VERSION "can_gui protocol 2"

NS_ :

BS_:

BU_: GUI MCU

BO_ 2559879867 GUI_COMMAND: 8 GUI
 SG_ CommandCode M : 0|8@1+ (1,0) [0|255] "" MCU
 SG_ Slot1Enable m1 : 8|1@1+ (1,0) [0|1] "" MCU
 SG_ Slot1ExtendedId m1 : 9|1@1+ (1,0) [0|1] "" MCU
 SG_ Slot1FlagsReserved m1 : 10|6@1+ (1,0) [0|0] "" MCU
 SG_ Slot1CanId m1 : 16|32@1+ (1,0) [0|536870911] "" MCU
 SG_ Slot1CycleTime m1 : 48|16@1+ (1,0) [1|65535] "ms" MCU
 SG_ Slot2Enable m2 : 8|1@1+ (1,0) [0|1] "" MCU
 SG_ Slot2ExtendedId m2 : 9|1@1+ (1,0) [0|1] "" MCU
 SG_ Slot2FlagsReserved m2 : 10|6@1+ (1,0) [0|0] "" MCU
 SG_ Slot2CanId m2 : 16|32@1+ (1,0) [0|536870911] "" MCU
 SG_ Slot2CycleTime m2 : 48|16@1+ (1,0) [1|65535] "ms" MCU
 SG_ LedChannel m16 : 8|8@1+ (1,0) [1|2] "" MCU
 SG_ LedState m16 : 16|8@1+ (1,0) [0|1] "" MCU
 SG_ LedReserved m16 : 24|40@1+ (1,0) [0|0] "" MCU
 SG_ Slot1CounterReserved1 m17 : 8|8@1+ (1,0) [0|0] "" MCU
 SG_ Slot1CounterLimit m17 : 16|32@1+ (1,0) [0|4294967295] "" MCU
 SG_ Slot1CounterReserved2 m17 : 48|16@1+ (1,0) [0|0] "" MCU
 SG_ Slot2CounterReserved1 m18 : 8|8@1+ (1,0) [0|0] "" MCU
 SG_ Slot2CounterLimit m18 : 16|32@1+ (1,0) [0|4294967295] "" MCU
 SG_ Slot2CounterReserved2 m18 : 48|16@1+ (1,0) [0|0] "" MCU
 SG_ RtcTimeHour m32 : 8|8@1+ (1,0) [0|23] "h" MCU
 SG_ RtcTimeMinute m32 : 16|8@1+ (1,0) [0|59] "min" MCU
 SG_ RtcTimeSecond m32 : 24|8@1+ (1,0) [0|59] "s" MCU
 SG_ RtcTimeReserved m32 : 32|32@1+ (1,0) [0|0] "" MCU
 SG_ RtcDateTimeHundredth m33 : 8|8@1+ (1,0) [0|99] "10 ms" MCU
 SG_ RtcDateTimeSecond m33 : 16|8@1+ (1,0) [0|59] "s" MCU
 SG_ RtcDateTimeMinute m33 : 24|8@1+ (1,0) [0|59] "min" MCU
 SG_ RtcDateTimeHour m33 : 32|8@1+ (1,0) [0|23] "h" MCU
 SG_ RtcDateTimeDay m33 : 40|8@1+ (1,0) [1|31] "" MCU
 SG_ RtcDateTimeMonth m33 : 48|5@1+ (1,0) [1|12] "" MCU
 SG_ RtcDateTimeWeekday m33 : 53|3@1+ (1,0) [0|6] "" MCU
 SG_ RtcDateTimeYear m33 : 56|8@1+ (1,0) [0|99] "" MCU
 SG_ AlarmSecondEnabled m34 : 8|1@1+ (1,0) [0|1] "" MCU
 SG_ AlarmMinuteEnabled m34 : 9|1@1+ (1,0) [0|1] "" MCU
 SG_ AlarmHourEnabled m34 : 10|1@1+ (1,0) [0|1] "" MCU
 SG_ AlarmDayEnabled m34 : 11|1@1+ (1,0) [0|1] "" MCU
 SG_ AlarmWeekdayEnabled m34 : 12|1@1+ (1,0) [0|1] "" MCU
 SG_ AlarmFlagsReserved m34 : 13|3@1+ (1,0) [0|0] "" MCU
 SG_ AlarmSecond m34 : 16|8@1+ (1,0) [0|59] "s" MCU
 SG_ AlarmMinute m34 : 24|8@1+ (1,0) [0|59] "min" MCU
 SG_ AlarmHour m34 : 32|8@1+ (1,0) [0|23] "h" MCU
 SG_ AlarmDay m34 : 40|8@1+ (1,0) [0|31] "" MCU
 SG_ AlarmWeekday m34 : 48|8@1+ (1,0) [0|6] "" MCU
 SG_ AlarmReserved m34 : 56|8@1+ (1,0) [0|0] "" MCU
 SG_ LogGetInfoReserved m48 : 8|56@1+ (1,0) [0|0] "" MCU
 SG_ LogReadSequence m49 : 8|32@1+ (1,0) [1|4294967295] "" MCU
 SG_ LogReadReserved m49 : 40|24@1+ (1,0) [0|0] "" MCU
 SG_ PwmFrequency m64 : 8|32@1+ (1,0) [0|1000000] "Hz" MCU
 SG_ PwmDutyCycle m64 : 40|8@1+ (1,0) [0|100] "%" MCU
 SG_ PwmReserved m64 : 48|16@1+ (1,0) [0|0] "" MCU
 SG_ PwmSelfTestStart m65 : 8|8@1+ (1,0) [0|1] "" MCU
 SG_ PwmSelfTestReserved m65 : 16|48@1+ (1,0) [0|0] "" MCU
 SG_ Tic12400BatterySwitchBitmap m80 : 8|24@1+ (1,0) [0|1023] "" MCU
 SG_ Tic12400PolarityReserved m80 : 32|32@1+ (1,0) [0|0] "" MCU

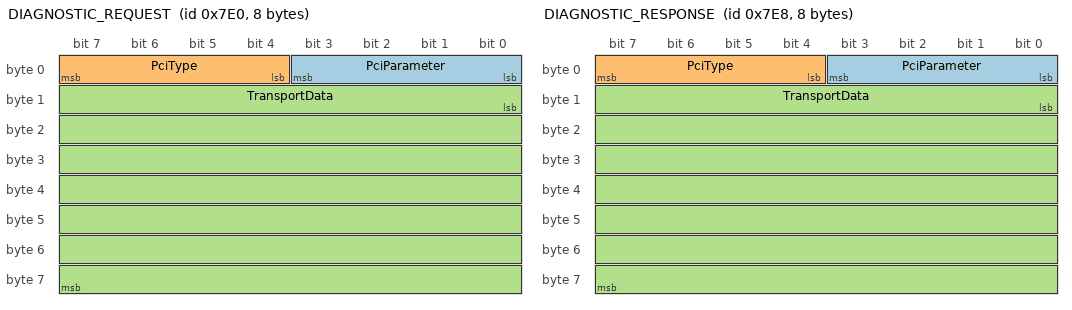
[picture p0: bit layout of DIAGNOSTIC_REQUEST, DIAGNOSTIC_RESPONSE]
BO_ 2016 DIAGNOSTIC_REQUEST: 8 GUI
 SG_ PciParameter : 0|4@1+ (1,0) [0|15] "" MCU
 SG_ PciType : 4|4@1+ (1,0) [0|3] "" MCU
 SG_ TransportData : 8|56@1+ (1,0) [0|72057594037927935] "" MCU

BO_ 2024 DIAGNOSTIC_RESPONSE: 8 MCU
 SG_ PciParameter : 0|4@1+ (1,0) [0|15] "" GUI
 SG_ PciType : 4|4@1+ (1,0) [0|3] "" GUI
 SG_ TransportData : 8|56@1+ (1,0) [0|72057594037927935] "" GUI

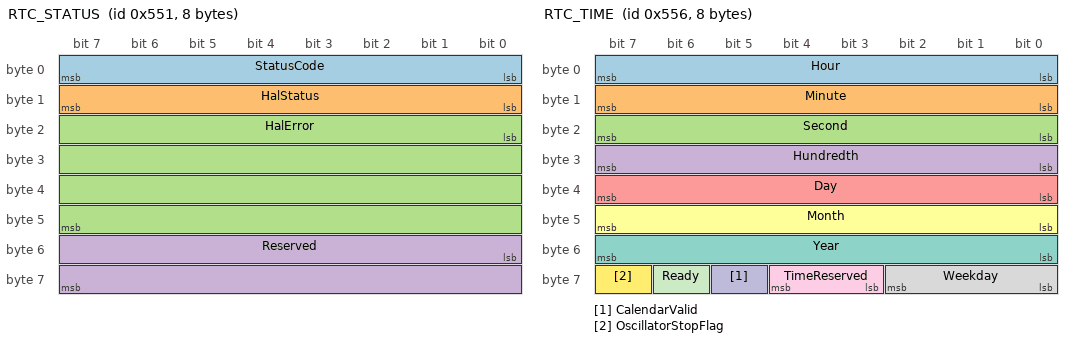
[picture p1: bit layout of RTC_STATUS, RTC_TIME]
BO_ 1361 RTC_STATUS: 8 MCU
 SG_ StatusCode : 0|8@1+ (1,0) [0|255] "" GUI
 SG_ HalStatus : 8|8@1+ (1,0) [0|255] "" GUI
 SG_ HalError : 16|32@1+ (1,0) [0|4294967295] "" GUI
 SG_ Reserved : 48|16@1+ (1,0) [0|0] "" GUI

BO_ 1366 RTC_TIME: 8 MCU
 SG_ Hour : 0|8@1+ (1,0) [0|23] "h" GUI
 SG_ Minute : 8|8@1+ (1,0) [0|59] "min" GUI
 SG_ Second : 16|8@1+ (1,0) [0|59] "s" GUI
 SG_ Hundredth : 24|8@1+ (1,0) [0|99] "10 ms" GUI
 SG_ Day : 32|8@1+ (1,0) [1|31] "" GUI
 SG_ Month : 40|8@1+ (1,0) [1|12] "" GUI
 SG_ Year : 48|8@1+ (1,0) [0|99] "" GUI
 SG_ Weekday : 56|3@1+ (1,0) [0|6] "" GUI
 SG_ TimeReserved : 59|2@1+ (1,0) [0|0] "" GUI
 SG_ CalendarValid : 61|1@1+ (1,0) [0|1] "" GUI
 SG_ Ready : 62|1@1+ (1,0) [0|1] "" GUI
 SG_ OscillatorStopFlag : 63|1@1+ (1,0) [0|1] "" GUI

BO_ 1367 SYSTEM_STATUS: 8 MCU
 SG_ Slot1Running : 0|1@1+ (1,0) [0|1] "" GUI
 SG_ Slot2Running : 1|1@1+ (1,0) [0|1] "" GUI
 SG_ Led1On : 2|1@1+ (1,0) [0|1] "" GUI
 SG_ Led2On : 3|1@1+ (1,0) [0|1] "" GUI
 SG_ SummaryReserved : 4|4@1+ (1,0) [0|0] "" GUI
 SG_ Slot1State : 8|8@1+ (1,0) [0|1] "" GUI
 SG_ Slot2State : 16|8@1+ (1,0) [0|1] "" GUI
 SG_ Led1State : 24|8@1+ (1,0) [0|1] "" GUI
 SG_ Led2State : 32|8@1+ (1,0) [0|1] "" GUI
 SG_ Slot1Requested : 40|1@1+ (1,0) [0|1] "" GUI
 SG_ Slot2Requested : 41|1@1+ (1,0) [0|1] "" GUI
 SG_ Led1Requested : 42|1@1+ (1,0) [0|1] "" GUI
 SG_ Led2Requested : 43|1@1+ (1,0) [0|1] "" GUI
 SG_ PwmRequested : 44|1@1+ (1,0) [0|1] "" GUI
 SG_ RequestReserved : 45|3@1+ (1,0) [0|0] "" GUI
 SG_ SwitchDataValid : 48|1@1+ (1,0) [0|1] "" GUI
 SG_ In0Closed : 49|1@1+ (1,0) [0|1] "" GUI
 SG_ In1Closed : 50|1@1+ (1,0) [0|1] "" GUI
 SG_ In2Closed : 51|1@1+ (1,0) [0|1] "" GUI
 SG_ In3Closed : 52|1@1+ (1,0) [0|1] "" GUI
 SG_ PhysicalReserved : 53|3@1+ (1,0) [0|0] "" GUI
 SG_ Slot1Blocked : 56|1@1+ (1,0) [0|1] "" GUI
 SG_ Slot2Blocked : 57|1@1+ (1,0) [0|1] "" GUI
 SG_ Led1Overridden : 58|1@1+ (1,0) [0|1] "" GUI
 SG_ OverrideReserved3 : 59|1@1+ (1,0) [0|0] "" GUI
 SG_ PwmBlocked : 60|1@1+ (1,0) [0|1] "" GUI
 SG_ OverrideReserved5 : 61|3@1+ (1,0) [0|0] "" GUI

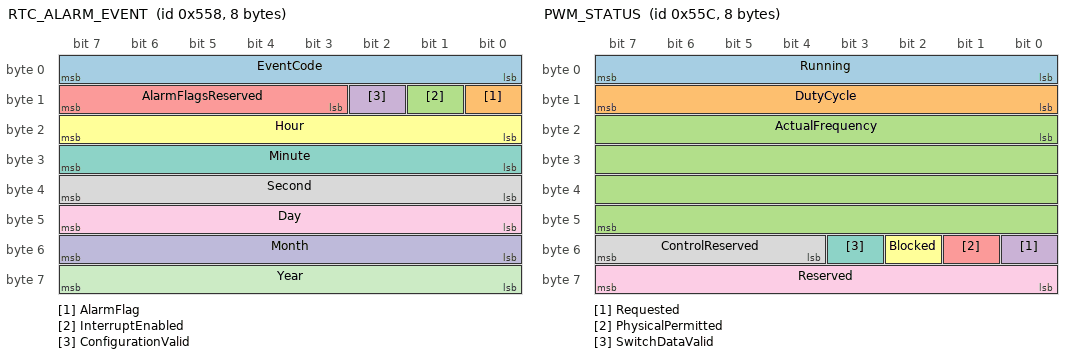
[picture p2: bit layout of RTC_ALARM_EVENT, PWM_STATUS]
BO_ 1368 RTC_ALARM_EVENT: 8 MCU
 SG_ EventCode : 0|8@1+ (1,0) [0|255] "" GUI
 SG_ AlarmFlag : 8|1@1+ (1,0) [0|1] "" GUI
 SG_ InterruptEnabled : 9|1@1+ (1,0) [0|1] "" GUI
 SG_ ConfigurationValid : 10|1@1+ (1,0) [0|1] "" GUI
 SG_ AlarmFlagsReserved : 11|5@1+ (1,0) [0|0] "" GUI
 SG_ Hour : 16|8@1+ (1,0) [0|23] "h" GUI
 SG_ Minute : 24|8@1+ (1,0) [0|59] "min" GUI
 SG_ Second : 32|8@1+ (1,0) [0|59] "s" GUI
 SG_ Day : 40|8@1+ (1,0) [1|31] "" GUI
 SG_ Month : 48|8@1+ (1,0) [1|12] "" GUI
 SG_ Year : 56|8@1+ (1,0) [0|99] "" GUI

BO_ 1372 PWM_STATUS: 8 MCU
 SG_ Running : 0|8@1+ (1,0) [0|1] "" GUI
 SG_ DutyCycle : 8|8@1+ (1,0) [0|100] "%" GUI
 SG_ ActualFrequency : 16|32@1+ (1,0) [0|4294967295] "Hz" GUI
 SG_ Requested : 48|1@1+ (1,0) [0|1] "" GUI
 SG_ PhysicalPermitted : 49|1@1+ (1,0) [0|1] "" GUI
 SG_ Blocked : 50|1@1+ (1,0) [0|1] "" GUI
 SG_ SwitchDataValid : 51|1@1+ (1,0) [0|1] "" GUI
 SG_ ControlReserved : 52|4@1+ (1,0) [0|0] "" GUI
 SG_ Reserved : 56|8@1+ (1,0) [0|0] "" GUI

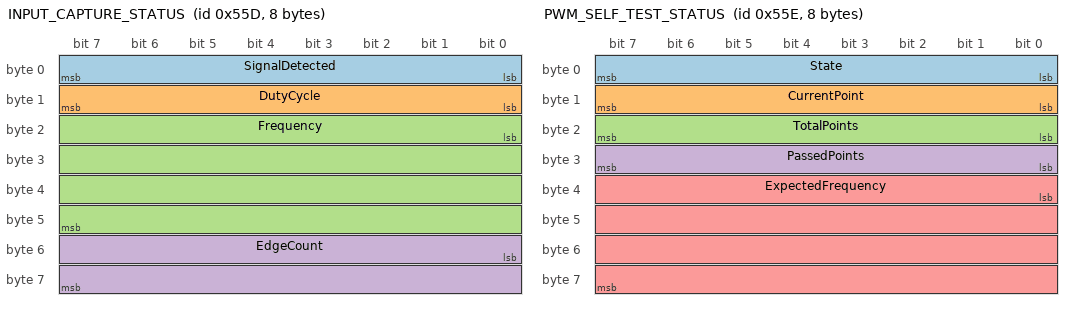
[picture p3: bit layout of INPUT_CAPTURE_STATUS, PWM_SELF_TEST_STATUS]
BO_ 1373 INPUT_CAPTURE_STATUS: 8 MCU
 SG_ SignalDetected : 0|8@1+ (1,0) [0|1] "" GUI
 SG_ DutyCycle : 8|8@1+ (1,0) [0|100] "%" GUI
 SG_ Frequency : 16|32@1+ (1,0) [0|4294967295] "Hz" GUI
 SG_ EdgeCount : 48|16@1+ (1,0) [0|65535] "" GUI

BO_ 1374 PWM_SELF_TEST_STATUS: 8 MCU
 SG_ State : 0|8@1+ (1,0) [0|5] "" GUI
 SG_ CurrentPoint : 8|8@1+ (1,0) [0|255] "" GUI
 SG_ TotalPoints : 16|8@1+ (1,0) [0|255] "" GUI
 SG_ PassedPoints : 24|8@1+ (1,0) [0|255] "" GUI
 SG_ ExpectedFrequency : 32|32@1+ (1,0) [0|4294967295] "Hz" GUI

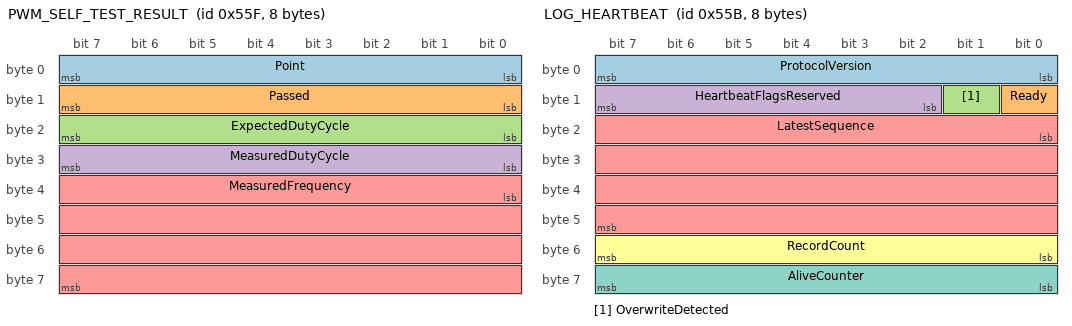
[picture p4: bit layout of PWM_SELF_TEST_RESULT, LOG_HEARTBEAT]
BO_ 1375 PWM_SELF_TEST_RESULT: 8 MCU
 SG_ Point : 0|8@1+ (1,0) [0|255] "" GUI
 SG_ Passed : 8|8@1+ (1,0) [0|1] "" GUI
 SG_ ExpectedDutyCycle : 16|8@1+ (1,0) [0|100] "%" GUI
 SG_ MeasuredDutyCycle : 24|8@1+ (1,0) [0|100] "%" GUI
 SG_ MeasuredFrequency : 32|32@1+ (1,0) [0|4294967295] "Hz" GUI

BO_ 1370 LOG_RESPONSE: 8 MCU
 SG_ FragmentHeader : 0|8@1+ (1,0) [0|255] "" GUI
 SG_ FragmentData : 8|56@1+ (1,0) [0|72057594037927935] "" GUI

BO_ 1371 LOG_HEARTBEAT: 8 MCU
 SG_ ProtocolVersion : 0|8@1+ (1,0) [0|255] "" GUI
 SG_ Ready : 8|1@1+ (1,0) [0|1] "" GUI
 SG_ OverwriteDetected : 9|1@1+ (1,0) [0|1] "" GUI
 SG_ HeartbeatFlagsReserved : 10|6@1+ (1,0) [0|0] "" GUI
 SG_ LatestSequence : 16|32@1+ (1,0) [0|4294967295] "" GUI
 SG_ RecordCount : 48|8@1+ (1,0) [0|64] "" GUI
 SG_ AliveCounter : 56|8@1+ (1,0) [0|255] "" GUI

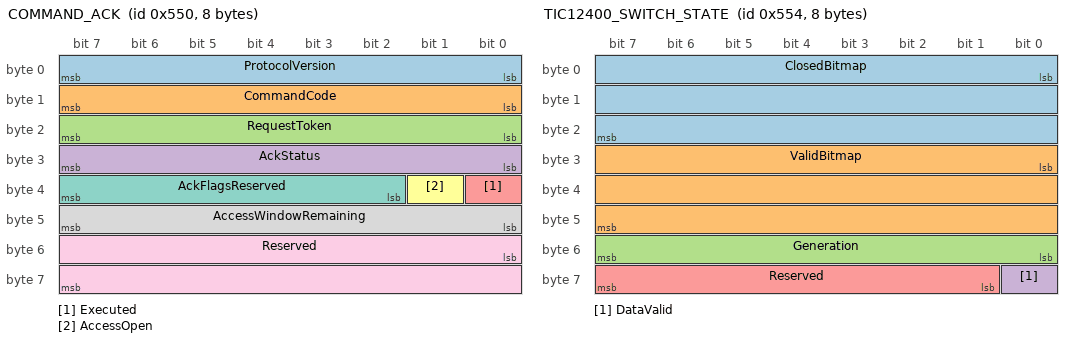
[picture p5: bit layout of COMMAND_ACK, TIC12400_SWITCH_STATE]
BO_ 1360 COMMAND_ACK: 8 MCU
 SG_ ProtocolVersion : 0|8@1+ (1,0) [0|255] "" GUI
 SG_ CommandCode : 8|8@1+ (1,0) [0|255] "" GUI
 SG_ RequestToken : 16|8@1+ (1,0) [0|255] "" GUI
 SG_ AckStatus : 24|8@1+ (1,0) [0|255] "" GUI
 SG_ Executed : 32|1@1+ (1,0) [0|1] "" GUI
 SG_ AccessOpen : 33|1@1+ (1,0) [0|1] "" GUI
 SG_ AckFlagsReserved : 34|6@1+ (1,0) [0|0] "" GUI
 SG_ AccessWindowRemaining : 40|8@1+ (1,0) [0|255] "s" GUI
 SG_ Reserved : 48|16@1+ (1,0) [0|0] "" GUI

BO_ 1362 TIC12400_STATUS: 8 MCU
 SG_ Online : 0|1@1+ (1,0) [0|1] "" GUI
 SG_ ConfigurationValid : 1|1@1+ (1,0) [0|1] "" GUI
 SG_ CrcComplete : 2|1@1+ (1,0) [0|1] "" GUI
 SG_ Monitoring : 3|1@1+ (1,0) [0|1] "" GUI
 SG_ StatusReserved4 : 4|1@1+ (1,0) [0|0] "" GUI
 SG_ PorObserved : 5|1@1+ (1,0) [0|1] "" GUI
 SG_ ServiceFault : 6|1@1+ (1,0) [0|1] "" GUI
 SG_ StatusReserved7 : 7|1@1+ (1,0) [0|0] "" GUI
 SG_ DeviceId : 8|8@1+ (1,0) [0|255] "" GUI
 SG_ ServiceResult : 16|8@1+ (1,0) [0|255] "" GUI
 SG_ SpiFail : 24|1@1+ (1,0) [0|1] "" GUI
 SG_ ParityFail : 25|1@1+ (1,0) [0|1] "" GUI
 SG_ SwitchStateChange : 26|1@1+ (1,0) [0|1] "" GUI
 SG_ SupplyThreshold : 27|1@1+ (1,0) [0|1] "" GUI
 SG_ Temperature : 28|1@1+ (1,0) [0|1] "" GUI
 SG_ OtherInterrupt : 29|1@1+ (1,0) [0|1] "" GUI
 SG_ PowerOnReset : 30|1@1+ (1,0) [0|1] "" GUI
 SG_ TransactionReserved : 31|1@1+ (1,0) [0|0] "" GUI
 SG_ ServiceFailureCount : 32|16@1+ (1,0) [0|65535] "" GUI
 SG_ LastInterruptStatus : 48|16@1+ (1,0) [0|65535] "" GUI

BO_ 1364 TIC12400_SWITCH_STATE: 8 MCU
 SG_ ClosedBitmap : 0|24@1+ (1,0) [0|16777215] "" GUI
 SG_ ValidBitmap : 24|24@1+ (1,0) [0|16777215] "" GUI
 SG_ Generation : 48|8@1+ (1,0) [0|255] "" GUI
 SG_ DataValid : 56|1@1+ (1,0) [0|1] "" GUI
 SG_ Reserved : 57|7@1+ (1,0) [0|0] "" GUI

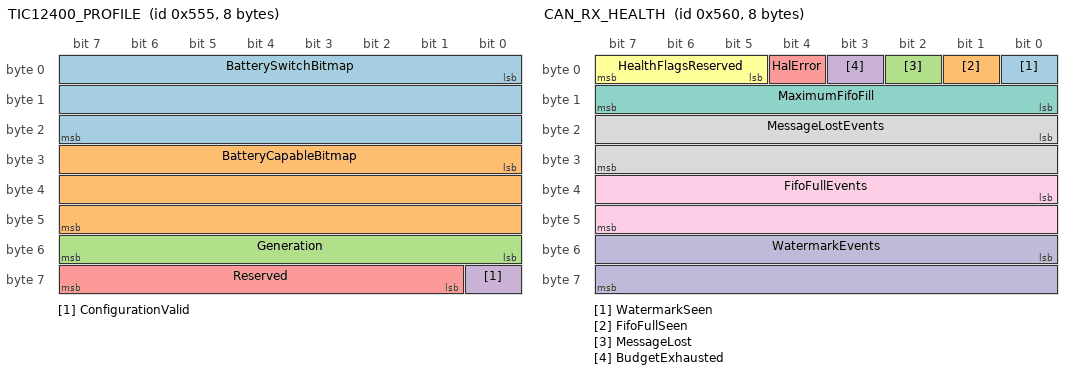
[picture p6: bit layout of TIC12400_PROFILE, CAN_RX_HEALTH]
BO_ 1365 TIC12400_PROFILE: 8 MCU
 SG_ BatterySwitchBitmap : 0|24@1+ (1,0) [0|16777215] "" GUI
 SG_ BatteryCapableBitmap : 24|24@1+ (1,0) [0|16777215] "" GUI
 SG_ Generation : 48|8@1+ (1,0) [0|255] "" GUI
 SG_ ConfigurationValid : 56|1@1+ (1,0) [0|1] "" GUI
 SG_ Reserved : 57|7@1+ (1,0) [0|0] "" GUI

BO_ 1376 CAN_RX_HEALTH: 8 MCU
 SG_ WatermarkSeen : 0|1@1+ (1,0) [0|1] "" GUI
 SG_ FifoFullSeen : 1|1@1+ (1,0) [0|1] "" GUI
 SG_ MessageLost : 2|1@1+ (1,0) [0|1] "" GUI
 SG_ BudgetExhausted : 3|1@1+ (1,0) [0|1] "" GUI
 SG_ HalError : 4|1@1+ (1,0) [0|1] "" GUI
 SG_ HealthFlagsReserved : 5|3@1+ (1,0) [0|0] "" GUI
 SG_ MaximumFifoFill : 8|8@1+ (1,0) [0|255] "" GUI
 SG_ MessageLostEvents : 16|16@1+ (1,0) [0|65535] "" GUI
 SG_ FifoFullEvents : 32|16@1+ (1,0) [0|65535] "" GUI
 SG_ WatermarkEvents : 48|16@1+ (1,0) [0|65535] "" GUI

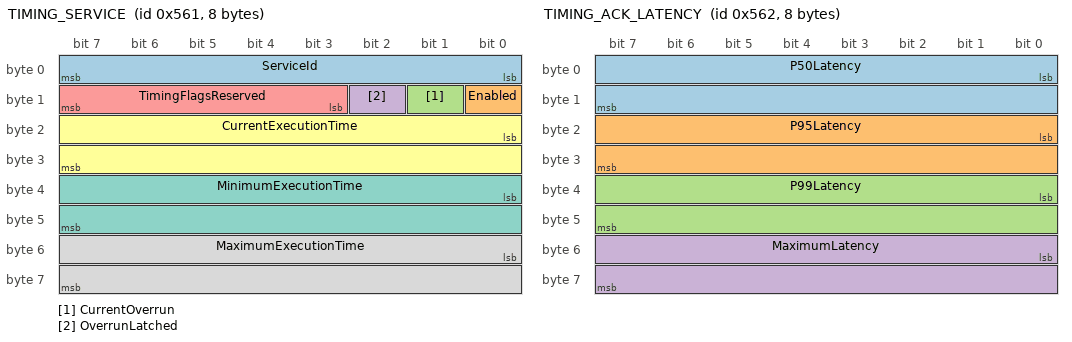
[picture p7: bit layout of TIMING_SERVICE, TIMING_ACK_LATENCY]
BO_ 1377 TIMING_SERVICE: 8 MCU
 SG_ ServiceId : 0|8@1+ (1,0) [0|7] "" GUI
 SG_ Enabled : 8|1@1+ (1,0) [0|1] "" GUI
 SG_ CurrentOverrun : 9|1@1+ (1,0) [0|1] "" GUI
 SG_ OverrunLatched : 10|1@1+ (1,0) [0|1] "" GUI
 SG_ TimingFlagsReserved : 11|5@1+ (1,0) [0|0] "" GUI
 SG_ CurrentExecutionTime : 16|16@1+ (1,0) [0|65535] "us" GUI
 SG_ MinimumExecutionTime : 32|16@1+ (1,0) [0|65535] "us" GUI
 SG_ MaximumExecutionTime : 48|16@1+ (1,0) [0|65535] "us" GUI

BO_ 1378 TIMING_ACK_LATENCY: 8 MCU
 SG_ P50Latency : 0|16@1+ (1,0) [0|65535] "us" GUI
 SG_ P95Latency : 16|16@1+ (1,0) [0|65535] "us" GUI
 SG_ P99Latency : 32|16@1+ (1,0) [0|65535] "us" GUI
 SG_ MaximumLatency : 48|16@1+ (1,0) [0|65535] "us" GUI

CM_ BO_ 2559879867 "Fixed identifier for all multiplexed GUI commands";
CM_ SG_ 2559879867 CommandCode "Selects the command-specific payload layout";
CM_ SG_ 2559879867 RtcDateTimeYear "Year offset from 2000";
CM_ BO_ 2016 "Physical ISO-TP diagnostic request to the MCU";
CM_ SG_ 2016 PciParameter "Length high nibble, sequence number or flow status";
CM_ SG_ 2016 PciType "ISO-TP protocol control information type";
CM_ SG_ 2016 TransportData "ISO-TP frame-dependent length, control or payload data";
CM_ BO_ 2024 "Physical ISO-TP diagnostic response from the MCU";
CM_ SG_ 2024 PciParameter "Length high nibble, sequence number or flow status";
CM_ SG_ 2024 PciType "ISO-TP protocol control information type";
CM_ SG_ 2024 TransportData "ISO-TP frame-dependent length, control or payload data";
CM_ BO_ 1361 "RTC operation status";
CM_ SG_ 1361 StatusCode "RTC operation result";
CM_ SG_ 1361 HalStatus "STM32 HAL operation status";
CM_ SG_ 1361 HalError "STM32 HAL I2C error bitmap";
CM_ SG_ 1361 Reserved "Reserved; transmit zero";
CM_ BO_ 1366 "RTC time and calendar";
CM_ SG_ 1366 Hundredth "Hundredths of a second";
CM_ SG_ 1366 Year "Year offset from 2000";
CM_ SG_ 1366 Weekday "PCA2131 weekday index; zero denotes Sunday";
CM_ SG_ 1366 TimeReserved "Reserved time flag bits; transmit zero";
CM_ SG_ 1366 CalendarValid "Calendar fields passed validation";
CM_ SG_ 1366 Ready "RTC service is ready";
CM_ SG_ 1366 OscillatorStopFlag "PCA2131 oscillator-stop flag is set";
CM_ BO_ 1367 "Slot and LED state";
CM_ SG_ 1367 SummaryReserved "Reserved summary bits; transmit zero";
CM_ SG_ 1367 Slot1State "Raw slot 1 running state";
CM_ SG_ 1367 Slot2State "Raw slot 2 running state";
CM_ SG_ 1367 Led1State "Raw LED 1 output state";
CM_ SG_ 1367 Led2State "Raw LED 2 output state";
CM_ SG_ 1367 RequestReserved "Reserved request bits; transmit zero";
CM_ SG_ 1367 PhysicalReserved "Reserved physical-input bits; transmit zero";
CM_ SG_ 1367 OverrideReserved3 "Reserved override bit; transmit zero";
CM_ SG_ 1367 OverrideReserved5 "Reserved override bits; transmit zero";
CM_ BO_ 1368 "RTC alarm event notification";
CM_ SG_ 1368 EventCode "RTC alarm event type";
CM_ SG_ 1368 AlarmFlag "PCA2131 alarm flag";
CM_ SG_ 1368 AlarmFlagsReserved "Reserved alarm flag bits; transmit zero";
CM_ SG_ 1368 Year "Year offset from 2000";
CM_ BO_ 1372 "PWM output status";
CM_ SG_ 1372 Requested "Remote PWM output is requested";
CM_ SG_ 1372 PhysicalPermitted "Physical input policy permits PWM output";
CM_ SG_ 1372 ControlReserved "Reserved control-policy bits; transmit zero";
CM_ SG_ 1372 Reserved "Reserved; transmit zero";
CM_ BO_ 1373 "Input capture measurement with estimated edge count";
CM_ SG_ 1373 EdgeCount "Saturating captured-edge count";
CM_ BO_ 1374 "PWM built-in self-test state and current target";
CM_ BO_ 1375 "PWM built-in self-test point result";
CM_ BO_ 1370 "STM32 event-log response fragments";
CM_ SG_ 1370 FragmentHeader "0x70-0x72 info, 0x80-0x84 record, or 0xF0 error";
CM_ SG_ 1370 FragmentData "Seven transport bytes; logical fields may cross frames";
CM_ BO_ 1371 "STM32 event-log heartbeat";
CM_ SG_ 1371 HeartbeatFlagsReserved "Reserved heartbeat flag bits; transmit zero";
CM_ SG_ 1371 AliveCounter "Wrapping heartbeat continuity counter";
CM_ BO_ 1360 "Command execution acknowledgement";
CM_ SG_ 1360 ProtocolVersion "Protocol version used to encode this acknowledgement";
CM_ SG_ 1360 CommandCode "Acknowledged GUI command";
CM_ SG_ 1360 RequestToken "CRC-8/SAE-J1850 token of the request payload";
CM_ SG_ 1360 AckStatus "Command validation and execution result";
CM_ SG_ 1360 Executed "Command handler completed successfully";
CM_ SG_ 1360 AccessOpen "Control-access window is open";
CM_ SG_ 1360 AckFlagsReserved "Reserved acknowledgement flag bits; transmit zero";
CM_ SG_ 1360 AccessWindowRemaining "Ceiling of remaining control-access time";
CM_ SG_ 1360 Reserved "Reserved; transmit zero";
CM_ BO_ 1362 "TIC12400 device and service status";
CM_ SG_ 1362 Online "TIC12400 communication is online";
CM_ SG_ 1362 ConfigurationValid "Startup register configuration passed readback";
CM_ SG_ 1362 CrcComplete "TIC12400 configuration CRC completed";
CM_ SG_ 1362 Monitoring "Switch monitoring is active";
CM_ SG_ 1362 StatusReserved4 "Reserved status bit; transmit zero";
CM_ SG_ 1362 PorObserved "Power-on-reset indication was observed";
CM_ SG_ 1362 ServiceFault "Latest TIC12400 service operation failed";
CM_ SG_ 1362 StatusReserved7 "Reserved status bit; transmit zero";
CM_ SG_ 1362 DeviceId "TIC12400 device identifier register value";
CM_ SG_ 1362 ServiceResult "Latest TIC12400 service result";
CM_ SG_ 1362 SpiFail "Device reported an SPI error";
CM_ SG_ 1362 ParityFail "Device reported a parity error";
CM_ SG_ 1362 SwitchStateChange "Switch-state-change interrupt was observed";
CM_ SG_ 1362 SupplyThreshold "Supply-threshold interrupt was observed";
CM_ SG_ 1362 Temperature "Temperature interrupt was observed";
CM_ SG_ 1362 OtherInterrupt "Other device interrupt was observed";
CM_ SG_ 1362 PowerOnReset "Transaction reported power-on reset";
CM_ SG_ 1362 TransactionReserved "Reserved transaction bit; transmit zero";
CM_ SG_ 1362 ServiceFailureCount "Saturating TIC12400 service failure count";
CM_ SG_ 1362 LastInterruptStatus "Last nonzero TIC12400 interrupt status";
CM_ BO_ 1364 "Debounced TIC12400 open/closed switch state";
CM_ SG_ 1364 ClosedBitmap "One bit per channel; one denotes a closed switch";
CM_ SG_ 1364 ValidBitmap "One bit per channel; one denotes valid switch data";
CM_ SG_ 1364 Generation "Switch-state generation counter";
CM_ SG_ 1364 DataValid "The switch-state frame is valid";
CM_ SG_ 1364 Reserved "Reserved; transmit zero";
CM_ BO_ 1365 "Applied TIC12400 switch-polarity profile";
CM_ SG_ 1365 BatterySwitchBitmap "One bit per channel; one selects battery switching";
CM_ SG_ 1365 BatteryCapableBitmap "One bit per channel; one denotes battery capability";
CM_ SG_ 1365 Generation "Applied profile generation counter";
CM_ SG_ 1365 ConfigurationValid "The applied polarity profile is valid";
CM_ SG_ 1365 Reserved "Reserved; transmit zero";
CM_ BO_ 1376 "MCU FDCAN RX FIFO pressure and loss telemetry";
CM_ SG_ 1376 HealthFlagsReserved "Reserved health flag bits; transmit zero";
CM_ SG_ 1376 MaximumFifoFill "Maximum observed RX FIFO fill level";
CM_ SG_ 1376 MessageLostEvents "Saturating RX message-lost event count";
CM_ SG_ 1376 FifoFullEvents "Saturating RX FIFO-full event count";
CM_ SG_ 1376 WatermarkEvents "Saturating RX watermark event count";
CM_ BO_ 1377 "DWT service execution timing telemetry";
CM_ SG_ 1377 TimingFlagsReserved "Reserved timing flag bits; transmit zero";
CM_ BO_ 1378 "Command RX-to-ACK enqueue latency percentiles";

BA_DEF_ BO_ "VFrameFormat" ENUM "StandardCAN","ExtendedCAN";
BA_DEF_DEF_ "VFrameFormat" "StandardCAN";
BA_ "VFrameFormat" BO_ 2559879867 1;

VAL_ 2559879867 CommandCode 1 "SET_SLOT_1" 2 "SET_SLOT_2" 16 "LED_CONTROL" 17 "START_SLOT_1_COUNTER" 18 "START_SLOT_2_COUNTER" 32 "RTC_SET_TIME" 33 "RTC_SET_DATETIME" 34 "RTC_SET_ALARM" 64 "PWM_SET" 65 "PWM_SELF_TEST" 48 "LOG_GET_INFO" 49 "LOG_READ_SEQUENCE" 80 "TIC12400_SET_POLARITY" ;

VAL_ 2559879867 Slot1Enable 0 "False" 1 "True" ;
VAL_ 2559879867 Slot1ExtendedId 0 "False" 1 "True" ;
VAL_ 2559879867 Slot2Enable 0 "False" 1 "True" ;
VAL_ 2559879867 Slot2ExtendedId 0 "False" 1 "True" ;
VAL_ 2559879867 LedState 0 "False" 1 "True" ;
VAL_ 2559879867 AlarmSecondEnabled 0 "False" 1 "True" ;
VAL_ 2559879867 AlarmMinuteEnabled 0 "False" 1 "True" ;
VAL_ 2559879867 AlarmHourEnabled 0 "False" 1 "True" ;
VAL_ 2559879867 AlarmDayEnabled 0 "False" 1 "True" ;
VAL_ 2559879867 AlarmWeekdayEnabled 0 "False" 1 "True" ;
VAL_ 2559879867 PwmSelfTestStart 0 "False" 1 "True" ;
VAL_ 2016 PciType 0 "SingleFrame" 1 "FirstFrame" 2 "ConsecutiveFrame" 3 "FlowControl" ;
VAL_ 2024 PciType 0 "SingleFrame" 1 "FirstFrame" 2 "ConsecutiveFrame" 3 "FlowControl" ;
VAL_ 1361 StatusCode 161 "INIT_OK" 162 "WRITE_VERIFY_OK" 163 "LINK_RECOVERED" 164 "ALARM_WRITE_VERIFY_OK" 225 "INIT_FAILED" 226 "READ_FAILED" 228 "INVALID_DATETIME" 229 "CONTROL_READ_FAILED" 230 "STOP_ASSERT_FAILED" 231 "PRESCALER_RESET_FAILED" 232 "CALENDAR_WRITE_FAILED" 233 "STOP_RELEASE_FAILED" 234 "RECOVERY_FAILED" 235 "BUSY" 236 "ALARM_NOT_READY" 237 "INVALID_ALARM_CONFIG" 238 "ALARM_WRITE_FAILED" 239 "ALARM_READBACK_FAILED" 240 "ALARM_VERIFY_MISMATCH" 241 "ALARM_FLAG_CLEAR_FAILED" 242 "WRITE_VERIFY_MISMATCH" ;
VAL_ 1366 CalendarValid 0 "False" 1 "True" ;
VAL_ 1366 Ready 0 "False" 1 "True" ;
VAL_ 1366 OscillatorStopFlag 0 "False" 1 "True" ;
VAL_ 1367 Slot1Running 0 "False" 1 "True" ;
VAL_ 1367 Slot2Running 0 "False" 1 "True" ;
VAL_ 1367 Led1On 0 "False" 1 "True" ;
VAL_ 1367 Led2On 0 "False" 1 "True" ;
VAL_ 1367 Slot1State 0 "False" 1 "True" ;
VAL_ 1367 Slot2State 0 "False" 1 "True" ;
VAL_ 1367 Led1State 0 "False" 1 "True" ;
VAL_ 1367 Led2State 0 "False" 1 "True" ;
VAL_ 1367 Slot1Requested 0 "False" 1 "True" ;
VAL_ 1367 Slot2Requested 0 "False" 1 "True" ;
VAL_ 1367 Led1Requested 0 "False" 1 "True" ;
VAL_ 1367 Led2Requested 0 "False" 1 "True" ;
VAL_ 1367 PwmRequested 0 "False" 1 "True" ;
VAL_ 1367 SwitchDataValid 0 "False" 1 "True" ;
VAL_ 1367 In0Closed 0 "False" 1 "True" ;
VAL_ 1367 In1Closed 0 "False" 1 "True" ;
VAL_ 1367 In2Closed 0 "False" 1 "True" ;
VAL_ 1367 In3Closed 0 "False" 1 "True" ;
VAL_ 1367 Slot1Blocked 0 "False" 1 "True" ;
VAL_ 1367 Slot2Blocked 0 "False" 1 "True" ;
VAL_ 1367 Led1Overridden 0 "False" 1 "True" ;
VAL_ 1367 PwmBlocked 0 "False" 1 "True" ;
VAL_ 1368 EventCode 1 "TRIGGERED" ;
VAL_ 1368 AlarmFlag 0 "False" 1 "True" ;
VAL_ 1368 InterruptEnabled 0 "False" 1 "True" ;
VAL_ 1368 ConfigurationValid 0 "False" 1 "True" ;
VAL_ 1372 Running 0 "False" 1 "True" ;
VAL_ 1372 Requested 0 "False" 1 "True" ;
VAL_ 1372 PhysicalPermitted 0 "False" 1 "True" ;
VAL_ 1372 Blocked 0 "False" 1 "True" ;
VAL_ 1372 SwitchDataValid 0 "False" 1 "True" ;
VAL_ 1373 SignalDetected 0 "False" 1 "True" ;
VAL_ 1374 State 0 "IDLE" 1 "RUNNING" 2 "PASSED" 3 "FAILED" 4 "CANCELLED" 5 "ERROR" ;
VAL_ 1375 Passed 0 "False" 1 "True" ;
VAL_ 1371 Ready 0 "False" 1 "True" ;
VAL_ 1371 OverwriteDetected 0 "False" 1 "True" ;
VAL_ 1376 WatermarkSeen 0 "False" 1 "True" ;
VAL_ 1376 FifoFullSeen 0 "False" 1 "True" ;
VAL_ 1376 MessageLost 0 "False" 1 "True" ;
VAL_ 1376 BudgetExhausted 0 "False" 1 "True" ;
VAL_ 1376 HalError 0 "False" 1 "True" ;
VAL_ 1377 ServiceId 0 "MAIN_LOOP" 1 "TIC12400_PROBE" 2 "CONTROL" 3 "RTC" 4 "INPUT_CAPTURE" 5 "CAN_APP" 6 "TIC12400_CAN" 7 "WATCHDOG" ;
VAL_ 1377 Enabled 0 "False" 1 "True" ;
VAL_ 1377 CurrentOverrun 0 "False" 1 "True" ;
VAL_ 1377 OverrunLatched 0 "False" 1 "True" ;
VAL_ 1360 CommandCode 1 "SET_SLOT_1" 2 "SET_SLOT_2" 16 "LED_CONTROL" 17 "START_SLOT_1_COUNTER" 18 "START_SLOT_2_COUNTER" 32 "RTC_SET_TIME" 33 "RTC_SET_DATETIME" 34 "RTC_SET_ALARM" 64 "PWM_SET" 65 "PWM_SELF_TEST" 48 "LOG_GET_INFO" 49 "LOG_READ_SEQUENCE" 80 "TIC12400_SET_POLARITY" ;
VAL_ 1360 AckStatus 0 "ACCEPTED" 2 "INVALID_PAYLOAD" 3 "UNKNOWN_COMMAND" 4 "ACCESS_DENIED" ;
VAL_ 1360 Executed 0 "False" 1 "True" ;
VAL_ 1360 AccessOpen 0 "False" 1 "True" ;
VAL_ 1362 Online 0 "False" 1 "True" ;
VAL_ 1362 ConfigurationValid 0 "False" 1 "True" ;
VAL_ 1362 CrcComplete 0 "False" 1 "True" ;
VAL_ 1362 Monitoring 0 "False" 1 "True" ;
VAL_ 1362 PorObserved 0 "False" 1 "True" ;
VAL_ 1362 ServiceFault 0 "False" 1 "True" ;
VAL_ 1362 ServiceResult 0 "OK" 1 "INVALID_ARGUMENT" 2 "INVALID_ADDRESS" 3 "HAL_ERROR" 4 "RESPONSE_PARITY_ERROR" 5 "DEVICE_SPI_ERROR" 6 "DEVICE_PARITY_ERROR" 7 "DEVICE_ID_MISMATCH" 8 "INVALID_DATA" 9 "REGISTER_VERIFY_MISMATCH" 10 "CRC_TIMEOUT" 11 "CRC_COMPLETION_MISSING" 255 "UNKNOWN" ;
VAL_ 1362 SpiFail 0 "False" 1 "True" ;
VAL_ 1362 ParityFail 0 "False" 1 "True" ;
VAL_ 1362 SwitchStateChange 0 "False" 1 "True" ;
VAL_ 1362 SupplyThreshold 0 "False" 1 "True" ;
VAL_ 1362 Temperature 0 "False" 1 "True" ;
VAL_ 1362 OtherInterrupt 0 "False" 1 "True" ;
VAL_ 1362 PowerOnReset 0 "False" 1 "True" ;
VAL_ 1364 DataValid 0 "False" 1 "True" ;
VAL_ 1365 ConfigurationValid 0 "False" 1 "True" ;
